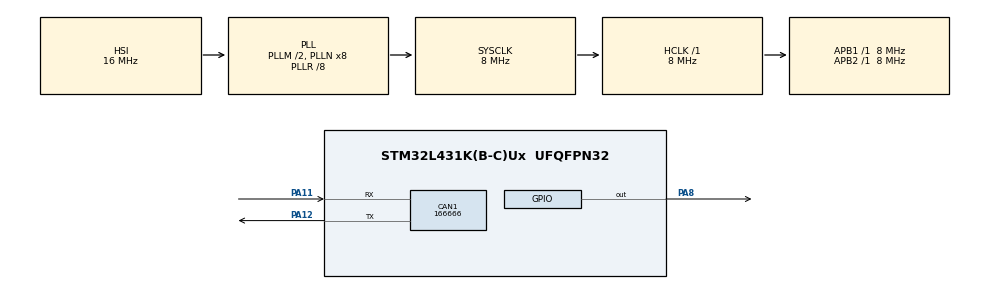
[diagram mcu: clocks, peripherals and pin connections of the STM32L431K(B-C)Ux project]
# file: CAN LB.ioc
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CAN1.CalculateBaudRate=166666
CAN1.CalculateTimeBit=6000.00
CAN1.CalculateTimeQuantum=2000.0
Mcu.Family=STM32L4
Mcu.Name=STM32L431K(B-C)Ux
Mcu.Package=UFQFPN32
NVIC.CAN1_RX0_IRQn=true\:0\:0\:false\:false\:true\:true\:true
NVIC.CAN1_TX_IRQn=true\:0\:0\:false\:false\:true\:true\:true
NVIC.PriorityGroup=NVIC_PRIORITYGROUP_4
PA11.Mode=CAN_Activate
PA11.Signal=CAN1_RX
PA12.Mode=CAN_Activate
PA12.Signal=CAN1_TX
PA8.Signal=GPIO_Output
ProjectManager.HeapSize=0x200
ProjectManager.StackSize=0x400
ProjectManager.TargetToolchain=STM32CubeIDE
RCC.ADCFreq_Value=32000000
RCC.AHBFreq_Value=8000000
RCC.APB1Freq_Value=8000000
RCC.APB1TimFreq_Value=8000000
RCC.APB2Freq_Value=8000000
RCC.APB2TimFreq_Value=8000000
RCC.CortexFreq_Value=8000000
RCC.HCLKFreq_Value=8000000
RCC.HSE_VALUE=8000000
RCC.HSI48_VALUE=48000000
RCC.HSI_VALUE=16000000
RCC.LSE_VALUE=32768
RCC.MSI_VALUE=4000000
RCC.PLLM=2
RCC.PLLR=RCC_PLLR_DIV8
RCC.PLLSourceVirtual=RCC_PLLSOURCE_HSI
RCC.SYSCLKFreq_VALUE=8000000
RCC.SYSCLKSource=RCC_SYSCLKSOURCE_PLLCLK
RCC.VCOOutputFreq_Value=64000000
board=custom

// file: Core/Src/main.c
/* USER CODE BEGIN Header */
/**
  ******************************************************************************
  * @file           : main.c
  * @brief          : Main program body
  ******************************************************************************
  * @attention
  *
  * <h2><center>&copy; Copyright (c) 2024 STMicroelectronics.
  * All rights reserved.</center></h2>
  *
  * This software component is licensed by ST under BSD 3-Clause license,
  * the "License"; You may not use this file except in compliance with the
  * License. You may obtain a copy of the License at:
  *                        opensource.org/licenses/BSD-3-Clause
  *
  ******************************************************************************
  */
/* USER CODE END Header */
#include "main.h"

CAN_HandleTypeDef hcan1;

void SystemClock_Config(void);
static void MX_GPIO_Init(void);
static void MX_CAN1_Init(void);

int main(void)
{

  /* MCU Configuration--------------------------------------------------------*/

  /* Reset of all peripherals, Initializes the Flash interface and the Systick. */
  HAL_Init();

  /* Configure the system clock */
  SystemClock_Config();

  /* Initialize all configured peripherals */
  MX_GPIO_Init();
  MX_CAN1_Init();
  /* USER CODE BEGIN 2 */
  HAL_GPIO_WritePin(GPIOA, GPIO_PIN_8, GPIO_PIN_RESET);
  HAL_CAN_Start(&hcan1);
  HAL_CAN_ActivateNotification(&hcan1, CAN_IT_RX_FIFO0_MSG_PENDING);

  CAN_TxHeaderTypeDef TxHeader;
  uint8_t TxData[8] = {0xAA, 0xBB, 0xCC, 0xDD, 0xEE, 0xFF, 0x00, 0x11};

  TxHeader.StdId = 0x123;
  TxHeader.DLC = 8;
  TxHeader.IDE = CAN_ID_STD;
  TxHeader.RTR = CAN_RTR_DATA;

  uint32_t TxMailbox = CAN_TX_MAILBOX0;
//  CAN_RxHeaderTypeDef RxHeader; //Header
//   uint8_t RxData[8]; //our buffer to recive data

  /* USER CODE END 2 */

  /* Infinite loop */
  /* USER CODE BEGIN WHILE */
  while (1)
  {
  	    HAL_CAN_AddTxMessage(&hcan1, &TxHeader, TxData, &TxMailbox);
//  	    HAL_CAN_GetRxMessage(&hcan1, CAN_RX_FIFO0, &RxHeader, RxData);

  	    HAL_Delay(1000);
    /* USER CODE END WHILE */

  }
}

void SystemClock_Config(void)
{
  RCC_OscInitTypeDef RCC_OscInitStruct = {0};
  RCC_ClkInitTypeDef RCC_ClkInitStruct = {0};

  /** Configure the main internal regulator output voltage
  */
  if (HAL_PWREx_ControlVoltageScaling(PWR_REGULATOR_VOLTAGE_SCALE1) != HAL_OK)
  {
    Error_Handler();
  }
  /** Initializes the RCC Oscillators according to the specified parameters
  * in the RCC_OscInitTypeDef structure.
  */
  RCC_OscInitStruct.OscillatorType = RCC_OSCILLATORTYPE_HSI;
  RCC_OscInitStruct.HSIState = RCC_HSI_ON;
  RCC_OscInitStruct.HSICalibrationValue = RCC_HSICALIBRATION_DEFAULT;
  RCC_OscInitStruct.PLL.PLLState = RCC_PLL_ON;
  RCC_OscInitStruct.PLL.PLLSource = RCC_PLLSOURCE_HSI;
  RCC_OscInitStruct.PLL.PLLM = 2;
  RCC_OscInitStruct.PLL.PLLN = 8;
  RCC_OscInitStruct.PLL.PLLP = RCC_PLLP_DIV7;
  RCC_OscInitStruct.PLL.PLLQ = RCC_PLLQ_DIV2;
  RCC_OscInitStruct.PLL.PLLR = RCC_PLLR_DIV8;
  if (HAL_RCC_OscConfig(&RCC_OscInitStruct) != HAL_OK)
  {
    Error_Handler();
  }
  /** Initializes the CPU, AHB and APB buses clocks
  */
  RCC_ClkInitStruct.ClockType = RCC_CLOCKTYPE_HCLK|RCC_CLOCKTYPE_SYSCLK
                              |RCC_CLOCKTYPE_PCLK1|RCC_CLOCKTYPE_PCLK2;
  RCC_ClkInitStruct.SYSCLKSource = RCC_SYSCLKSOURCE_PLLCLK;
  RCC_ClkInitStruct.AHBCLKDivider = RCC_SYSCLK_DIV1;
  RCC_ClkInitStruct.APB1CLKDivider = RCC_HCLK_DIV1;
  RCC_ClkInitStruct.APB2CLKDivider = RCC_HCLK_DIV1;

  if (HAL_RCC_ClockConfig(&RCC_ClkInitStruct, FLASH_LATENCY_0) != HAL_OK)
  {
    Error_Handler();
  }
}

static void MX_CAN1_Init(void)
{

  hcan1.Instance = CAN1;
  hcan1.Init.Prescaler = 2;
  hcan1.Init.Mode = CAN_MODE_NORMAL;
  hcan1.Init.SyncJumpWidth = CAN_SJW_1TQ;
  hcan1.Init.TimeSeg1 = CAN_BS1_13TQ;
  hcan1.Init.TimeSeg2 = CAN_BS2_2TQ;
  hcan1.Init.TimeTriggeredMode = DISABLE;
  hcan1.Init.AutoBusOff = DISABLE;
  hcan1.Init.AutoWakeUp = DISABLE;
  hcan1.Init.AutoRetransmission = DISABLE;
  hcan1.Init.ReceiveFifoLocked = DISABLE;
  hcan1.Init.TransmitFifoPriority = DISABLE;
  if (HAL_CAN_Init(&hcan1) != HAL_OK)
  {
    Error_Handler();
  }

}

static void MX_GPIO_Init(void)
{
  GPIO_InitTypeDef GPIO_InitStruct = {0};

  /* GPIO Ports Clock Enable */
  __HAL_RCC_GPIOA_CLK_ENABLE();

  /*Configure GPIO pin Output Level */
  HAL_GPIO_WritePin(GPIOA, GPIO_PIN_8, GPIO_PIN_RESET);

  /*Configure GPIO pin : PA8 */
  GPIO_InitStruct.Pin = GPIO_PIN_8;
  GPIO_InitStruct.Mode = GPIO_MODE_OUTPUT_PP;
  GPIO_InitStruct.Pull = GPIO_NOPULL;
  GPIO_InitStruct.Speed = GPIO_SPEED_FREQ_LOW;
  HAL_GPIO_Init(GPIOA, &GPIO_InitStruct);

}

void Error_Handler(void)
{
  __disable_irq();
  while (1)
  {
  }
}

/************************ (C) COPYRIGHT STMicroelectronics *****END OF FILE****/
